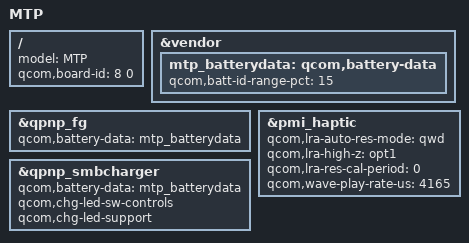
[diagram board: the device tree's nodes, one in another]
/*
 * Copyright (c) 2018, The Linux Foundation. All rights reserved.
 *
 * This program is free software; you can redistribute it and/or modify
 * it under the terms of the GNU General Public License version 2 and
 * only version 2 as published by the Free Software Foundation.
 *
 * This program is distributed in the hope that it will be useful,
 * but WITHOUT ANY WARRANTY; without even the implied warranty of
 * MERCHANTABILITY or FITNESS FOR A PARTICULAR PURPOSE.  See the
 * GNU General Public License for more details.
 */

/dts-v1/;
/plugin/;

#include "msm8953-mtp.dtsi"

/ {
	model = "MTP";
	qcom,board-id = <8 0>;
};

&vendor {
	mtp_batterydata: qcom,battery-data {
		qcom,batt-id-range-pct = <15>;
		#include "qg-batterydata-OPPO-DD003desay-ATL-4v4-4230mAh.dtsi"
		#include "qg-batterydata-OPPO-DD003desay-ATL_300-4v4-4230mAh.dtsi"
		#include "qg-batterydata-OPPO-DD003desay-SDI-4v4-4230mAh.dtsi"
		#include "qg-batterydata-OPPO-DD003desay-SDI_300-4v4-4230mAh.dtsi"
	};
};

&qpnp_fg {
	qcom,battery-data = <&mtp_batterydata>;
};

&pmi_haptic{
	qcom,lra-auto-res-mode="qwd";
	qcom,lra-high-z="opt1";
	qcom,lra-res-cal-period = <0>;
	qcom,wave-play-rate-us = <4165>;
};

&qpnp_smbcharger {
	qcom,battery-data = <&mtp_batterydata>;
	qcom,chg-led-sw-controls;
	qcom,chg-led-support;
};
